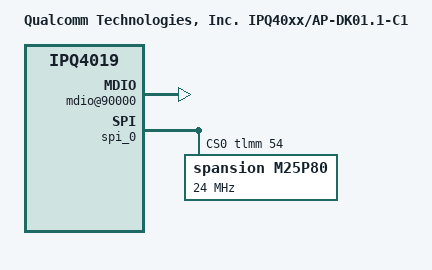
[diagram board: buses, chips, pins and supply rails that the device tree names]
/* Copyright (c) 2015 - 2106, The Linux Foundation. All rights reserved.
 *
 * Permission to use, copy, modify, and/or distribute this software for any
 * purpose with or without fee is hereby granted, provided that the above
 * copyright notice and this permission notice appear in all copies.
 *
 * THE SOFTWARE IS PROVIDED "AS IS" AND THE AUTHOR DISCLAIMS ALL WARRANTIES
 * WITH REGARD TO THIS SOFTWARE INCLUDING ALL IMPLIED WARRANTIES OF
 * MERCHANTABILITY AND FITNESS. IN NO EVENT SHALL THE AUTHOR BE LIABLE FOR
 * ANY SPECIAL, DIRECT, INDIRECT, OR CONSEQUENTIAL DAMAGES OR ANY DAMAGES
 * WHATSOEVER RESULTING FROM LOSS OF USE, DATA OR PROFITS, WHETHER IN AN
 * ACTION OF CONTRACT, NEGLIGENCE OR OTHER TORTIOUS ACTION, ARISING OUT OF
 * OR IN CONNECTION WITH THE USE OR PERFORMANCE OF THIS SOFTWARE.
 *
 */

#include "qcom-ipq4019-ap.dk01.1.dtsi"

/ {
	model = "Qualcomm Technologies, Inc. IPQ40xx/AP-DK01.1-C1";

	soc {
		mdio@90000 {
			status = "ok";
			pinctrl-0 = <&mdio_pins>;
			pinctrl-names = "default";
			bias-disable;
			phy-reset-gpio = <&tlmm 62 0>;
		};
		
		spi_0: spi@78b5000 { /* BLSP1 QUP1 */
			status = "ok";
			cs-gpios = <&tlmm 54 0>;
			num-cs = <1>;

			m25p80@0 {
				#address-cells = <1>;
				#size-cells = <1>;
				compatible = "spansion,m25p80", "jedec,spi-nor";
				reg = <0>;
				spi-max-frequency = <24000000>;
				m25p,fast-read;
			};
		};

	};

};
